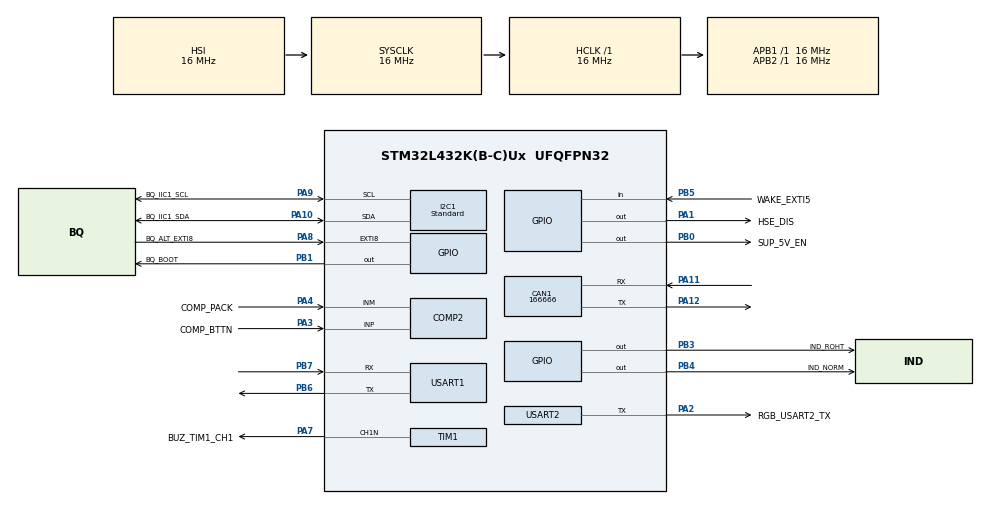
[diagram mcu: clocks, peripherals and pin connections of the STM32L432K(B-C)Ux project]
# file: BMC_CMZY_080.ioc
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CAN1.BS1=CAN_BS1_4TQ
CAN1.BS2=CAN_BS2_1TQ
CAN1.CalculateBaudRate=166666
CAN1.CalculateTimeBit=6000
CAN1.CalculateTimeQuantum=1000.0
Dma.I2C1_RX.0.Direction=DMA_PERIPH_TO_MEMORY
Dma.I2C1_RX.0.Instance=DMA1_Channel7
Dma.I2C1_RX.0.MemDataAlignment=DMA_MDATAALIGN_BYTE
Dma.I2C1_RX.0.MemInc=DMA_MINC_ENABLE
Dma.I2C1_RX.0.Mode=DMA_NORMAL
Dma.I2C1_RX.0.PeriphDataAlignment=DMA_PDATAALIGN_BYTE
Dma.I2C1_RX.0.PeriphInc=DMA_PINC_DISABLE
Dma.I2C1_RX.0.Priority=DMA_PRIORITY_LOW
Dma.I2C1_TX.1.Direction=DMA_MEMORY_TO_PERIPH
Dma.I2C1_TX.1.Instance=DMA1_Channel6
Dma.I2C1_TX.1.MemDataAlignment=DMA_MDATAALIGN_BYTE
Dma.I2C1_TX.1.MemInc=DMA_MINC_ENABLE
Dma.I2C1_TX.1.Mode=DMA_NORMAL
Dma.I2C1_TX.1.PeriphDataAlignment=DMA_PDATAALIGN_BYTE
Dma.I2C1_TX.1.PeriphInc=DMA_PINC_DISABLE
Dma.I2C1_TX.1.Priority=DMA_PRIORITY_LOW
Dma.Request0=I2C1_RX
Dma.Request1=I2C1_TX
I2C1.CustomTiming=Enabled
I2C1.I2C_Coeff_DF=4
I2C1.I2C_Speed_Mode=I2C_Standard
I2C1.Speed=100
I2C1.Timing=0x1424A4FF
Mcu.Family=STM32L4
Mcu.Name=STM32L432K(B-C)Ux
Mcu.Package=UFQFPN32
NVIC.DMA1_Channel6_IRQn=true\:0\:0\:false\:false\:true\:false\:true\:true
NVIC.DMA1_Channel7_IRQn=true\:0\:0\:false\:false\:true\:false\:true\:true
NVIC.PriorityGroup=NVIC_PRIORITYGROUP_4
NVIC.TIM2_IRQn=true\:0\:0\:false\:false\:true\:true\:true\:true
PA0.Mode=HSE-External-Clock-Source-for-LittleOrca
PA0.Signal=RCC_CK_IN
PA1.GPIO_Label=HSE_DIS
PA1.Signal=GPIO_Output
PA10.GPIO_Label=BQ_IIC1_SDA
PA10.GPIO_Pu=GPIO_PULLUP
PA10.Mode=I2C
PA10.Signal=I2C1_SDA
PA11.Mode=CAN_Activate
PA11.Signal=CAN1_RX
PA12.Mode=CAN_Activate
PA12.Signal=CAN1_TX
PA13\ (JTMS-SWDIO).Mode=Serial_Wire
PA13\ (JTMS-SWDIO).Signal=SYS_JTMS-SWDIO
PA14\ (JTCK-SWCLK).Mode=Serial_Wire
PA14\ (JTCK-SWCLK).Signal=SYS_JTCK-SWCLK
PA2.GPIO_Label=RGB_USART2_TX
PA2.Mode=Half_duplex(single_wire_mode)
PA2.Signal=USART2_TX
PA3.GPIO_Label=COMP_BTTN
PA3.Mode=INP
PA3.Signal=COMP2_INP
PA4.GPIO_Label=COMP_PACK
PA4.Mode=INM
PA4.Signal=COMP2_INM
PA7.GPIO_Label=BUZ_TIM1_CH1
PA7.Mode=PWM Generation1 CH1N
PA7.Signal=TIM1_CH1N
PA8.GPIO_Label=BQ_ALT_EXTI8
PA8.GPIO_ModeDefaultEXTI=GPIO_MODE_EVT_RISING
PA8.Signal=GPXTI8
PA9.GPIO_Label=BQ_IIC1_SCL
PA9.GPIO_Pu=GPIO_PULLUP
PA9.Mode=I2C
PA9.Signal=I2C1_SCL
PB0.GPIO_Label=SUP_5V_EN
PB0.Signal=GPIO_Output
PB1.GPIO_Label=BQ_BOOT
PB1.Signal=GPIO_Output
PB3\ (JTDO-TRACESWO).GPIO_Label=IND_ROHT
PB3\ (JTDO-TRACESWO).Signal=GPIO_Output
PB4\ (NJTRST).GPIO_Label=IND_NORM
PB4\ (NJTRST).Signal=GPIO_Output
PB5.GPIO_Label=WAKE_EXTI5
PB5.GPIO_PuPd=GPIO_PULLUP
PB5.Signal=GPIO_Input
PB6.Mode=Asynchronous
PB6.Signal=USART1_TX
PB7.Mode=Asynchronous
PB7.Signal=USART1_RX
PC14-OSC32_IN\ (PC14).Mode=LSE-External-Oscillator
PC14-OSC32_IN\ (PC14).Signal=RCC_OSC32_IN
PC15-OSC32_OUT\ (PC15).Mode=LSE-External-Oscillator
PC15-OSC32_OUT\ (PC15).Signal=RCC_OSC32_OUT
ProjectManager.HeapSize=0x200
ProjectManager.StackSize=0x400
ProjectManager.TargetToolchain=Makefile
RCC.ADCFreq_Value=64000000
RCC.AHBFreq_Value=16000000
RCC.APB1Freq_Value=16000000
RCC.APB1TimFreq_Value=16000000
RCC.APB2Freq_Value=16000000
RCC.APB2TimFreq_Value=16000000
RCC.CortexFreq_Value=16000000
RCC.HCLKFreq_Value=16000000
RCC.HSE_VALUE=12000000
RCC.HSI48_VALUE=48000000
RCC.HSI_VALUE=16000000
RCC.I2C1CLockSelection=RCC_I2C1CLKSOURCE_SYSCLK
RCC.LPTIM1CLockSelection=RCC_LPTIM1CLKSOURCE_LSI
RCC.RTCClockSelection=RCC_RTCCLKSOURCE_LSI
RCC.MSI_VALUE=4000000
RCC.PLLN=10
RCC.PLLSourceVirtual=RCC_PLLSOURCE_HSI
RCC.PWR_Regulator_Voltage_Scale=PWR_REGULATOR_VOLTAGE_SCALE2
RCC.SYSCLKFreq_VALUE=16000000
RCC.SYSCLKSource=RCC_SYSCLKSOURCE_HSI
RCC.USBFreq_Value=64000000
RCC.VCOOutputFreq_Value=160000000
TIM1.Channel-PWM\ Generation1\ CH1N=TIM_CHANNEL_1
TIM2.Channel-Output\ Compare1\ No\ Output=TIM_CHANNEL_1
TIM2.TIM_MasterSlaveMode=TIM_MASTERSLAVEMODE_ENABLE
USART1.VirtualMode-Asynchronous=VM_ASYNC
USART2.Mode=MODE_TX
USART2.VirtualMode-Half_duplex(single_wire_mode)=VM_ASYNC
VP_DAC1_VS_DACI1.Mode=DAC_OUT1_Int
VP_IWDG_VS_IWDG.Mode=IWDG_Activate
VP_LPTIM1_VS_LPTIM_counterModeInternalClock.Mode=Counts__internal_clock_event_00
VP_RTC_VS_RTC_Activate.Mode=RTC_Enabled
VP_TIM1_VS_ClockSourceINT.Mode=Internal
VP_TIM2_VS_ClockSourceINT.Mode=Internal
VP_TIM2_VS_no_output1.Mode=Output Compare1 No Output
board=custom

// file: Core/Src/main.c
/* USER CODE BEGIN Header */
/**
  ******************************************************************************
  * @file           : main.c
  * @brief          : Main program body
  ******************************************************************************
  * @attention
  *
  * Copyright (c) 2026 STMicroelectronics.
  * All rights reserved.
  *
  * This software is licensed under terms that can be found in the LICENSE file
  * in the root directory of this software component.
  * If no LICENSE file comes with this software, it is provided AS-IS.
  *
  ******************************************************************************
  */
/* USER CODE END Header */
#include "main.h"

/* USER CODE BEGIN Includes */
#include "app/main_app.h"
#include "app/watchdog.h"
/* USER CODE END Includes */

CAN_HandleTypeDef hcan1;

COMP_HandleTypeDef hcomp2;

DAC_HandleTypeDef hdac1;

I2C_HandleTypeDef hi2c1;
DMA_HandleTypeDef hdma_i2c1_rx;
DMA_HandleTypeDef hdma_i2c1_tx;

IWDG_HandleTypeDef hiwdg;

LPTIM_HandleTypeDef hlptim1;

RTC_HandleTypeDef hrtc;

TIM_HandleTypeDef htim1;
TIM_HandleTypeDef htim2;

UART_HandleTypeDef huart1;
UART_HandleTypeDef huart2;

void SystemClock_Config(void);
static void MX_GPIO_Init(void);
static void MX_DMA_Init(void);
static void MX_CAN1_Init(void);
static void MX_COMP2_Init(void);
static void MX_DAC1_Init(void);
static void MX_I2C1_Init(void);
static void MX_USART1_UART_Init(void);
static void MX_USART2_UART_Init(void);
static void MX_TIM1_Init(void);
static void MX_RTC_Init(void);
static void MX_TIM2_Init(void);
static void MX_LPTIM1_Init(void);
static void MX_IWDG_Init(void);

int main(void)
{

  /* MCU Configuration--------------------------------------------------------*/

  /* Reset of all peripherals, Initializes the Flash interface and the Systick. */
  HAL_Init();

  /* USER CODE BEGIN Init */
  /* Defensive legacy LSE-CSS cleanup.  Current IOC has EnableCSSLSE=false and
   * the firmware never enables it; an old build may have left LSECSSON/D set
   * in the backup domain.  Clear it before the RTC source helper runs so a
   * dead LSE cannot hold boot.  A BDRST here clears BKP (LP session) once. */
  __HAL_RCC_PWR_CLK_ENABLE();
  HAL_PWR_EnableBkUpAccess();
  if ((RCC->BDCR & (RCC_BDCR_LSECSSON | RCC_BDCR_LSECSSD)) != 0u)
  {
      SET_BIT(RCC->BDCR, RCC_BDCR_BDRST);
      CLEAR_BIT(RCC->BDCR, RCC_BDCR_BDRST);
  }
  /* USER CODE END Init */

  /* Configure the system clock */
  SystemClock_Config();

  /* USER CODE BEGIN SysInit */
  /* Keep LSE CSS off; the current IOC does not enable it.  LSERDY is only a
   * diagnostic in LP_RTC_USE_LSE=1 builds (PowerMode_LseHealthTask()). */
  CLEAR_BIT(RCC->BDCR, RCC_BDCR_LSECSSON);
  /* USER CODE END SysInit */

  /* Initialize all configured peripherals */
  MX_GPIO_Init();
  MX_DMA_Init();
  MX_CAN1_Init();
  MX_COMP2_Init();
  MX_DAC1_Init();
  MX_I2C1_Init();
  MX_USART1_UART_Init();
  MX_USART2_UART_Init();
  MX_TIM1_Init();
  MX_RTC_Init();
  MX_TIM2_Init();
  MX_LPTIM1_Init();
  MX_IWDG_Init();
  /* USER CODE BEGIN 2 */
  App_Boot();
  /* USER CODE END 2 */

  /* Infinite loop */
  while (1)
  {

    /* USER CODE BEGIN 3 */
    App_Loop();
  }
  /* USER CODE END 3 */
}

void SystemClock_Config(void)
{
  RCC_OscInitTypeDef RCC_OscInitStruct = {0};
  RCC_ClkInitTypeDef RCC_ClkInitStruct = {0};

  /** Configure the main internal regulator output voltage
  */
  if (HAL_PWREx_ControlVoltageScaling(PWR_REGULATOR_VOLTAGE_SCALE2) != HAL_OK)
  {
    Error_Handler();
  }

  /** Initializes the RCC Oscillators according to the specified parameters
  * in the RCC_OscInitTypeDef structure.
  */
  /* Boot-safe patch: only HSI here.  The RTC source helper
   * (RtcTime_MspClockSource, called from MX_RTC_Init) starts LSE only when
   * LP_RTC_USE_LSE=1; LSI and IWDG enable their clocks later.  A dead/slow
   * LSE must not block boot in SystemClock_Config(). */
  RCC_OscInitStruct.OscillatorType = RCC_OSCILLATORTYPE_HSI;
  RCC_OscInitStruct.HSIState = RCC_HSI_ON;
  RCC_OscInitStruct.HSICalibrationValue = RCC_HSICALIBRATION_DEFAULT;
  RCC_OscInitStruct.PLL.PLLState = RCC_PLL_NONE;
  if (HAL_RCC_OscConfig(&RCC_OscInitStruct) != HAL_OK)
  {
    Error_Handler();
  }

  /** Initializes the CPU, AHB and APB buses clocks
  */
  RCC_ClkInitStruct.ClockType = RCC_CLOCKTYPE_HCLK|RCC_CLOCKTYPE_SYSCLK
                              |RCC_CLOCKTYPE_PCLK1|RCC_CLOCKTYPE_PCLK2;
  RCC_ClkInitStruct.SYSCLKSource = RCC_SYSCLKSOURCE_HSI;
  RCC_ClkInitStruct.AHBCLKDivider = RCC_SYSCLK_DIV1;
  RCC_ClkInitStruct.APB1CLKDivider = RCC_HCLK_DIV1;
  RCC_ClkInitStruct.APB2CLKDivider = RCC_HCLK_DIV1;

  if (HAL_RCC_ClockConfig(&RCC_ClkInitStruct, FLASH_LATENCY_2) != HAL_OK)
  {
    Error_Handler();
  }
}

static void MX_CAN1_Init(void)
{

  hcan1.Instance = CAN1;
  hcan1.Init.Prescaler = 16;
  hcan1.Init.Mode = CAN_MODE_NORMAL;
  hcan1.Init.SyncJumpWidth = CAN_SJW_1TQ;
  hcan1.Init.TimeSeg1 = CAN_BS1_4TQ;
  hcan1.Init.TimeSeg2 = CAN_BS2_1TQ;
  hcan1.Init.TimeTriggeredMode = DISABLE;
  hcan1.Init.AutoBusOff = DISABLE;
  hcan1.Init.AutoWakeUp = DISABLE;
  hcan1.Init.AutoRetransmission = DISABLE;
  hcan1.Init.ReceiveFifoLocked = DISABLE;
  hcan1.Init.TransmitFifoPriority = DISABLE;
  if (HAL_CAN_Init(&hcan1) != HAL_OK)
  {
    Error_Handler();
  }

}

static void MX_COMP2_Init(void)
{

  hcomp2.Instance = COMP2;
  hcomp2.Init.InvertingInput = COMP_INPUT_MINUS_IO4;
  hcomp2.Init.NonInvertingInput = COMP_INPUT_PLUS_IO3;
  hcomp2.Init.OutputPol = COMP_OUTPUTPOL_NONINVERTED;
  hcomp2.Init.Hysteresis = COMP_HYSTERESIS_NONE;
  hcomp2.Init.BlankingSrce = COMP_BLANKINGSRC_NONE;
  hcomp2.Init.Mode = COMP_POWERMODE_HIGHSPEED;
  hcomp2.Init.WindowMode = COMP_WINDOWMODE_DISABLE;
  hcomp2.Init.TriggerMode = COMP_TRIGGERMODE_NONE;
  if (HAL_COMP_Init(&hcomp2) != HAL_OK)
  {
    Error_Handler();
  }

}

static void MX_DAC1_Init(void)
{

  DAC_ChannelConfTypeDef sConfig = {0};

  /** DAC Initialization
  */
  hdac1.Instance = DAC1;
  if (HAL_DAC_Init(&hdac1) != HAL_OK)
  {
    Error_Handler();
  }

  /** DAC channel OUT1 config
  */
  sConfig.DAC_SampleAndHold = DAC_SAMPLEANDHOLD_DISABLE;
  sConfig.DAC_Trigger = DAC_TRIGGER_NONE;
  sConfig.DAC_OutputBuffer = DAC_OUTPUTBUFFER_DISABLE;
  sConfig.DAC_ConnectOnChipPeripheral = DAC_CHIPCONNECT_ENABLE;
  sConfig.DAC_UserTrimming = DAC_TRIMMING_FACTORY;
  if (HAL_DAC_ConfigChannel(&hdac1, &sConfig, DAC_CHANNEL_1) != HAL_OK)
  {
    Error_Handler();
  }

}

static void MX_I2C1_Init(void)
{

  hi2c1.Instance = I2C1;
  hi2c1.Init.Timing = 0x1424A4FF;
  hi2c1.Init.OwnAddress1 = 0;
  hi2c1.Init.AddressingMode = I2C_ADDRESSINGMODE_7BIT;
  hi2c1.Init.DualAddressMode = I2C_DUALADDRESS_DISABLE;
  hi2c1.Init.OwnAddress2 = 0;
  hi2c1.Init.OwnAddress2Masks = I2C_OA2_NOMASK;
  hi2c1.Init.GeneralCallMode = I2C_GENERALCALL_DISABLE;
  hi2c1.Init.NoStretchMode = I2C_NOSTRETCH_DISABLE;
  if (HAL_I2C_Init(&hi2c1) != HAL_OK)
  {
    Error_Handler();
  }

  /** Configure Analogue filter
  */
  if (HAL_I2CEx_ConfigAnalogFilter(&hi2c1, I2C_ANALOGFILTER_ENABLE) != HAL_OK)
  {
    Error_Handler();
  }

  /** Configure Digital filter
  */
  if (HAL_I2CEx_ConfigDigitalFilter(&hi2c1, 4) != HAL_OK)
  {
    Error_Handler();
  }

}

static void MX_IWDG_Init(void)
{

  hiwdg.Instance = IWDG;
  hiwdg.Init.Prescaler = IWDG_PRESCALER_4;
  hiwdg.Init.Window = 4095;
  hiwdg.Init.Reload = 4095;
  if (HAL_IWDG_Init(&hiwdg) != HAL_OK)
  {
    Error_Handler();
  }
  /* USER CODE BEGIN IWDG_Init 2 */
  /* CubeMX default is IWDG /4 (~0.5 s) and HAL_IWDG_Init has already started
   * it.  Immediately install the ~32.8 s boot guard so the reset-based LP
   * light path has time; App_Init later installs the ~8.2 s NORM dead-man. */
  Watchdog_Init();
  /* USER CODE END IWDG_Init 2 */

}

static void MX_LPTIM1_Init(void)
{

  hlptim1.Instance = LPTIM1;
  hlptim1.Init.Clock.Source = LPTIM_CLOCKSOURCE_APBCLOCK_LPOSC;
  hlptim1.Init.Clock.Prescaler = LPTIM_PRESCALER_DIV1;
  hlptim1.Init.Trigger.Source = LPTIM_TRIGSOURCE_SOFTWARE;
  hlptim1.Init.OutputPolarity = LPTIM_OUTPUTPOLARITY_HIGH;
  hlptim1.Init.UpdateMode = LPTIM_UPDATE_IMMEDIATE;
  hlptim1.Init.CounterSource = LPTIM_COUNTERSOURCE_INTERNAL;
  hlptim1.Init.Input1Source = LPTIM_INPUT1SOURCE_GPIO;
  hlptim1.Init.Input2Source = LPTIM_INPUT2SOURCE_GPIO;
  if (HAL_LPTIM_Init(&hlptim1) != HAL_OK)
  {
    Error_Handler();
  }

}

static void MX_RTC_Init(void)
{

  /** Initialize RTC Only
  */
  hrtc.Instance = RTC;
  hrtc.Init.HourFormat = RTC_HOURFORMAT_24;
  hrtc.Init.AsynchPrediv = 127;
  hrtc.Init.SynchPrediv = 255;
  hrtc.Init.OutPut = RTC_OUTPUT_DISABLE;
  hrtc.Init.OutPutRemap = RTC_OUTPUT_REMAP_NONE;
  hrtc.Init.OutPutPolarity = RTC_OUTPUT_POLARITY_HIGH;
  hrtc.Init.OutPutType = RTC_OUTPUT_TYPE_OPENDRAIN;
  if (HAL_RTC_Init(&hrtc) != HAL_OK)
  {
    Error_Handler();
  }

}

static void MX_TIM1_Init(void)
{

  TIM_ClockConfigTypeDef sClockSourceConfig = {0};
  TIM_MasterConfigTypeDef sMasterConfig = {0};
  TIM_OC_InitTypeDef sConfigOC = {0};
  TIM_BreakDeadTimeConfigTypeDef sBreakDeadTimeConfig = {0};

  htim1.Instance = TIM1;
  htim1.Init.Prescaler = 0;
  htim1.Init.CounterMode = TIM_COUNTERMODE_UP;
  htim1.Init.Period = 65535;
  htim1.Init.ClockDivision = TIM_CLOCKDIVISION_DIV1;
  htim1.Init.RepetitionCounter = 0;
  htim1.Init.AutoReloadPreload = TIM_AUTORELOAD_PRELOAD_DISABLE;
  if (HAL_TIM_Base_Init(&htim1) != HAL_OK)
  {
    Error_Handler();
  }
  sClockSourceConfig.ClockSource = TIM_CLOCKSOURCE_INTERNAL;
  if (HAL_TIM_ConfigClockSource(&htim1, &sClockSourceConfig) != HAL_OK)
  {
    Error_Handler();
  }
  if (HAL_TIM_PWM_Init(&htim1) != HAL_OK)
  {
    Error_Handler();
  }
  sMasterConfig.MasterOutputTrigger = TIM_TRGO_RESET;
  sMasterConfig.MasterOutputTrigger2 = TIM_TRGO2_RESET;
  sMasterConfig.MasterSlaveMode = TIM_MASTERSLAVEMODE_DISABLE;
  if (HAL_TIMEx_MasterConfigSynchronization(&htim1, &sMasterConfig) != HAL_OK)
  {
    Error_Handler();
  }
  sConfigOC.OCMode = TIM_OCMODE_PWM1;
  sConfigOC.Pulse = 0;
  sConfigOC.OCPolarity = TIM_OCPOLARITY_HIGH;
  sConfigOC.OCNPolarity = TIM_OCNPOLARITY_HIGH;
  sConfigOC.OCFastMode = TIM_OCFAST_DISABLE;
  sConfigOC.OCIdleState = TIM_OCIDLESTATE_RESET;
  sConfigOC.OCNIdleState = TIM_OCNIDLESTATE_RESET;
  if (HAL_TIM_PWM_ConfigChannel(&htim1, &sConfigOC, TIM_CHANNEL_1) != HAL_OK)
  {
    Error_Handler();
  }
  sBreakDeadTimeConfig.OffStateRunMode = TIM_OSSR_DISABLE;
  sBreakDeadTimeConfig.OffStateIDLEMode = TIM_OSSI_DISABLE;
  sBreakDeadTimeConfig.LockLevel = TIM_LOCKLEVEL_OFF;
  sBreakDeadTimeConfig.DeadTime = 0;
  sBreakDeadTimeConfig.BreakState = TIM_BREAK_DISABLE;
  sBreakDeadTimeConfig.BreakPolarity = TIM_BREAKPOLARITY_HIGH;
  sBreakDeadTimeConfig.BreakFilter = 0;
  sBreakDeadTimeConfig.Break2State = TIM_BREAK2_DISABLE;
  sBreakDeadTimeConfig.Break2Polarity = TIM_BREAK2POLARITY_HIGH;
  sBreakDeadTimeConfig.Break2Filter = 0;
  sBreakDeadTimeConfig.AutomaticOutput = TIM_AUTOMATICOUTPUT_DISABLE;
  if (HAL_TIMEx_ConfigBreakDeadTime(&htim1, &sBreakDeadTimeConfig) != HAL_OK)
  {
    Error_Handler();
  }
  HAL_TIM_MspPostInit(&htim1);

}

static void MX_TIM2_Init(void)
{

  TIM_ClockConfigTypeDef sClockSourceConfig = {0};
  TIM_MasterConfigTypeDef sMasterConfig = {0};
  TIM_OC_InitTypeDef sConfigOC = {0};

  htim2.Instance = TIM2;
  htim2.Init.Prescaler = 0;
  htim2.Init.CounterMode = TIM_COUNTERMODE_UP;
  htim2.Init.Period = 4294967295;
  htim2.Init.ClockDivision = TIM_CLOCKDIVISION_DIV1;
  htim2.Init.AutoReloadPreload = TIM_AUTORELOAD_PRELOAD_DISABLE;
  if (HAL_TIM_Base_Init(&htim2) != HAL_OK)
  {
    Error_Handler();
  }
  sClockSourceConfig.ClockSource = TIM_CLOCKSOURCE_INTERNAL;
  if (HAL_TIM_ConfigClockSource(&htim2, &sClockSourceConfig) != HAL_OK)
  {
    Error_Handler();
  }
  if (HAL_TIM_OC_Init(&htim2) != HAL_OK)
  {
    Error_Handler();
  }
  sMasterConfig.MasterOutputTrigger = TIM_TRGO_RESET;
  sMasterConfig.MasterSlaveMode = TIM_MASTERSLAVEMODE_ENABLE;
  if (HAL_TIMEx_MasterConfigSynchronization(&htim2, &sMasterConfig) != HAL_OK)
  {
    Error_Handler();
  }
  sConfigOC.OCMode = TIM_OCMODE_TIMING;
  sConfigOC.Pulse = 0;
  sConfigOC.OCPolarity = TIM_OCPOLARITY_HIGH;
  sConfigOC.OCFastMode = TIM_OCFAST_DISABLE;
  if (HAL_TIM_OC_ConfigChannel(&htim2, &sConfigOC, TIM_CHANNEL_1) != HAL_OK)
  {
    Error_Handler();
  }

}

static void MX_USART1_UART_Init(void)
{

  huart1.Instance = USART1;
  huart1.Init.BaudRate = 115200;
  huart1.Init.WordLength = UART_WORDLENGTH_8B;
  huart1.Init.StopBits = UART_STOPBITS_1;
  huart1.Init.Parity = UART_PARITY_NONE;
  huart1.Init.Mode = UART_MODE_TX_RX;
  huart1.Init.HwFlowCtl = UART_HWCONTROL_NONE;
  huart1.Init.OverSampling = UART_OVERSAMPLING_16;
  huart1.Init.OneBitSampling = UART_ONE_BIT_SAMPLE_DISABLE;
  huart1.AdvancedInit.AdvFeatureInit = UART_ADVFEATURE_NO_INIT;
  if (HAL_UART_Init(&huart1) != HAL_OK)
  {
    Error_Handler();
  }

}

static void MX_USART2_UART_Init(void)
{

  huart2.Instance = USART2;
  huart2.Init.BaudRate = 115200;
  huart2.Init.WordLength = UART_WORDLENGTH_8B;
  huart2.Init.StopBits = UART_STOPBITS_1;
  huart2.Init.Parity = UART_PARITY_NONE;
  huart2.Init.Mode = UART_MODE_TX;
  huart2.Init.HwFlowCtl = UART_HWCONTROL_NONE;
  huart2.Init.OverSampling = UART_OVERSAMPLING_16;
  huart2.Init.OneBitSampling = UART_ONE_BIT_SAMPLE_DISABLE;
  huart2.AdvancedInit.AdvFeatureInit = UART_ADVFEATURE_NO_INIT;
  if (HAL_HalfDuplex_Init(&huart2) != HAL_OK)
  {
    Error_Handler();
  }

}

static void MX_DMA_Init(void)
{

  /* DMA controller clock enable */
  __HAL_RCC_DMA1_CLK_ENABLE();

  /* DMA interrupt init */
  /* DMA1_Channel6_IRQn interrupt configuration */
  HAL_NVIC_SetPriority(DMA1_Channel6_IRQn, 0, 0);
  HAL_NVIC_EnableIRQ(DMA1_Channel6_IRQn);
  /* DMA1_Channel7_IRQn interrupt configuration */
  HAL_NVIC_SetPriority(DMA1_Channel7_IRQn, 0, 0);
  HAL_NVIC_EnableIRQ(DMA1_Channel7_IRQn);

}

static void MX_GPIO_Init(void)
{
  GPIO_InitTypeDef GPIO_InitStruct = {0};

  /* GPIO Ports Clock Enable */
  __HAL_RCC_GPIOC_CLK_ENABLE();
  __HAL_RCC_GPIOA_CLK_ENABLE();
  __HAL_RCC_GPIOB_CLK_ENABLE();

  /*Configure GPIO pin Output Level */
  HAL_GPIO_WritePin(HSE_DIS_GPIO_Port, HSE_DIS_Pin, GPIO_PIN_RESET);

  /*Configure GPIO pin Output Level */
  HAL_GPIO_WritePin(GPIOB, SUP_5V_EN_Pin|BQ_BOOT_Pin|IND_ROHT_Pin|IND_NORM_Pin, GPIO_PIN_RESET);

  /*Configure GPIO pin : HSE_DIS_Pin */
  GPIO_InitStruct.Pin = HSE_DIS_Pin;
  GPIO_InitStruct.Mode = GPIO_MODE_OUTPUT_PP;
  GPIO_InitStruct.Pull = GPIO_NOPULL;
  GPIO_InitStruct.Speed = GPIO_SPEED_FREQ_LOW;
  HAL_GPIO_Init(HSE_DIS_GPIO_Port, &GPIO_InitStruct);

  /*Configure GPIO pins : SUP_5V_EN_Pin BQ_BOOT_Pin IND_ROHT_Pin IND_NORM_Pin */
  GPIO_InitStruct.Pin = SUP_5V_EN_Pin|BQ_BOOT_Pin|IND_ROHT_Pin|IND_NORM_Pin;
  GPIO_InitStruct.Mode = GPIO_MODE_OUTPUT_PP;
  GPIO_InitStruct.Pull = GPIO_NOPULL;
  GPIO_InitStruct.Speed = GPIO_SPEED_FREQ_LOW;
  HAL_GPIO_Init(GPIOB, &GPIO_InitStruct);

  /*Configure GPIO pin : BQ_ALT_EXTI8_Pin */
  GPIO_InitStruct.Pin = BQ_ALT_EXTI8_Pin;
  GPIO_InitStruct.Mode = GPIO_MODE_EVT_RISING;
  GPIO_InitStruct.Pull = GPIO_NOPULL;
  HAL_GPIO_Init(BQ_ALT_EXTI8_GPIO_Port, &GPIO_InitStruct);

  /*Configure GPIO pin : WAKE_EXTI5_Pin */
  GPIO_InitStruct.Pin = WAKE_EXTI5_Pin;
  GPIO_InitStruct.Mode = GPIO_MODE_INPUT;
  GPIO_InitStruct.Pull = GPIO_PULLUP;
  HAL_GPIO_Init(WAKE_EXTI5_GPIO_Port, &GPIO_InitStruct);

}

void Error_Handler(void)
{
  __disable_irq();
  while (1)
  {
  }
}
